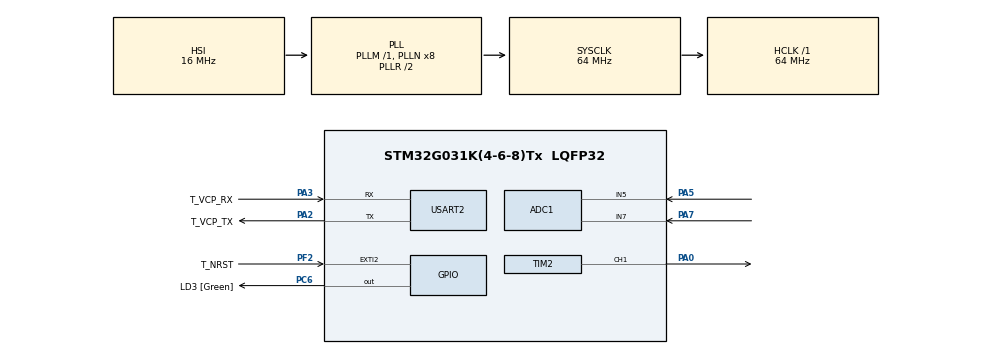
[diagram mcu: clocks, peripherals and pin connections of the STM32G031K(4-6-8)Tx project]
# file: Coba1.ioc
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ADC1.Channel-1\#ChannelRegularConversion=ADC_CHANNEL_7
ADC1.ContinuousConvMode=ENABLE
ADC1.NbrOfConversionFlag=1
ADC1.Rank-1\#ChannelRegularConversion=1
ADC1.SamplingTime-1\#ChannelRegularConversion=ADC_SAMPLINGTIME_COMMON_1
ADC1.SelectedChannel=ADC_CHANNEL_5|ADC_CHANNEL_7
ADC1.master=1
Mcu.Family=STM32G0
Mcu.Name=STM32G031K(4-6-8)Tx
Mcu.Package=LQFP32
NVIC.EXTI2_3_IRQn=true\:0\:0\:false\:false\:true\:true\:true
PA0.Signal=S_TIM2_CH1
PA13.GPIO_Label=T_JTMS
PA13.Mode=Serial_Wire
PA13.Signal=SYS_SWDIO
PA14-BOOT0.GPIO_Label=T_JTCK
PA14-BOOT0.Mode=Serial_Wire
PA14-BOOT0.Signal=SYS_SWCLK
PA2.GPIO_Label=T_VCP_TX
PA2.GPIO_PuPd=GPIO_PULLUP
PA2.Mode=Asynchronous
PA2.Signal=USART2_TX
PA3.GPIO_Label=T_VCP_RX
PA3.GPIO_PuPd=GPIO_PULLUP
PA3.Mode=Asynchronous
PA3.Signal=USART2_RX
PA5.Mode=IN5
PA5.Signal=ADC1_IN5
PA7.Mode=IN7
PA7.Signal=ADC1_IN7
PC14-OSC32_IN\ (PC14).Mode=LSE-External-Oscillator
PC14-OSC32_IN\ (PC14).Signal=RCC_OSC32_IN
PC15-OSC32_OUT\ (PC15).Mode=LSE-External-Oscillator
PC15-OSC32_OUT\ (PC15).Signal=RCC_OSC32_OUT
PC6.GPIO_Label=LD3 [Green]
PC6.Signal=GPIO_Output
PF2\ -\ NRST.GPIO_Label=T_NRST
PF2\ -\ NRST.GPIO_ModeDefaultEXTI=GPIO_MODE_IT_FALLING
PF2\ -\ NRST.GPIO_PuPd=GPIO_PULLUP
PF2\ -\ NRST.Signal=GPXTI2
ProjectManager.HeapSize=0x200
ProjectManager.StackSize=0x400
ProjectManager.TargetToolchain=MDK-ARM V5.27
RCC.ADCFreq_Value=64000000
RCC.AHBFreq_Value=64000000
RCC.APB1CLKDivider=RCC_HCLK_DIV2
RCC.CortexFreq_Value=64000000
RCC.EXTERNAL_CLOCK_VALUE=12288000
RCC.HCLKFreq_Value=64000000
RCC.HSE_VALUE=8000000
RCC.HSI_VALUE=16000000
RCC.SYSCLKFreq_VALUE=64000000
RCC.SYSCLKSource=RCC_SYSCLKSOURCE_PLLCLK
RCC.VCOOutputFreq_Value=128000000
SH.S_TIM2_CH1.0=TIM2_CH1,PWM Generation1 CH1
TIM1.Period=0xffff
TIM1.Prescaler=64-1
TIM2.AutoReloadPreload=TIM_AUTORELOAD_PRELOAD_ENABLE
TIM2.Channel-PWM\ Generation1\ CH1=TIM_CHANNEL_1
TIM2.Period=4294967295
USART2.VirtualMode-Asynchronous=VM_ASYNC
USART2.WordLength=WORDLENGTH_7B
VP_TIM1_VS_ClockSourceINT.Mode=Internal
board=NUCLEO-G031K8

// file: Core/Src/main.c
/* USER CODE BEGIN Header */
/**
  ******************************************************************************
  * @file           : main.c
  * @brief          : Main program body
  ******************************************************************************
  * @attention
  *
  * <h2><center>&copy; Copyright (c) 2022 STMicroelectronics.
  * All rights reserved.</center></h2>
  *
  * This software component is licensed by ST under BSD 3-Clause license,
  * the "License"; You may not use this file except in compliance with the
  * License. You may obtain a copy of the License at:
  *                        opensource.org/licenses/BSD-3-Clause
  *
  ******************************************************************************
  */
/* USER CODE END Header */
#include "main.h"

ADC_HandleTypeDef hadc1;

TIM_HandleTypeDef htim1;
TIM_HandleTypeDef htim2;

UART_HandleTypeDef huart2;

void SystemClock_Config(void);
static void MX_GPIO_Init(void);
static void MX_USART2_UART_Init(void);
static void MX_TIM1_Init(void);
static void MX_ADC1_Init(void);
static void MX_TIM2_Init(void);

/* USER CODE BEGIN 0 */
void delay_us (uint16_t us)
{
	__HAL_TIM_SET_COUNTER(&htim1,0);  // set the counter value a 0
	while (__HAL_TIM_GET_COUNTER(&htim1) < us);  // wait for the counter to reach the us input in the parameter
}

/*
void HAL_GPIO_EXTI_Falling_Callback(uint16_t GPIO_Pin)
{
    if(GPIO_Pin == GPIO_PIN_2) // If The INT Source Is EXTI Line9 (A9 Pin)
    {
			HAL_GPIO_TogglePin(GPIOC, GPIO_PIN_6); // Toggle The Output (LED) Pin
    }
}
*/
uint16_t AD_RES;
/* USER CODE END 0 */

int main(void)
{

  /* MCU Configuration--------------------------------------------------------*/

  /* Reset of all peripherals, Initializes the Flash interface and the Systick. */
  HAL_Init();

  /* Configure the system clock */
  SystemClock_Config();

  /* Initialize all configured peripherals */
  MX_GPIO_Init();
  MX_USART2_UART_Init();
  MX_TIM1_Init();
  MX_ADC1_Init();
  MX_TIM2_Init();
  /* USER CODE BEGIN 2 */
	HAL_TIM_Base_Start(&htim1);	// Start timer 1
	// Start ADC Conversion
	HAL_ADC_Start(&hadc1);
	//HAL_ADCEx_Calibration_Start(&hadc1);	// Calibrate ADC
  /* USER CODE END 2 */

  /* Infinite loop */
  /* USER CODE BEGIN WHILE */
  while (1)
  {
		// Poll ADC1 Perihperal & TimeOut = 1mSec
		HAL_ADC_PollForConversion(&hadc1, 1000);
		// Read The ADC Conversion Result & Map It To PWM DutyCycle
		AD_RES = HAL_ADC_GetValue(&hadc1);

		//HAL_GPIO_TogglePin(GPIOC, GPIO_PIN_6);
		//delay_us(65000);

    /* USER CODE END WHILE */

  }
}

void SystemClock_Config(void)
{
  RCC_OscInitTypeDef RCC_OscInitStruct = {0};
  RCC_ClkInitTypeDef RCC_ClkInitStruct = {0};
  RCC_PeriphCLKInitTypeDef PeriphClkInit = {0};

  /** Configure the main internal regulator output voltage
  */
  HAL_PWREx_ControlVoltageScaling(PWR_REGULATOR_VOLTAGE_SCALE1);
  /** Initializes the RCC Oscillators according to the specified parameters
  * in the RCC_OscInitTypeDef structure.
  */
  RCC_OscInitStruct.OscillatorType = RCC_OSCILLATORTYPE_HSI;
  RCC_OscInitStruct.HSIState = RCC_HSI_ON;
  RCC_OscInitStruct.HSIDiv = RCC_HSI_DIV1;
  RCC_OscInitStruct.HSICalibrationValue = RCC_HSICALIBRATION_DEFAULT;
  RCC_OscInitStruct.PLL.PLLState = RCC_PLL_ON;
  RCC_OscInitStruct.PLL.PLLSource = RCC_PLLSOURCE_HSI;
  RCC_OscInitStruct.PLL.PLLM = RCC_PLLM_DIV1;
  RCC_OscInitStruct.PLL.PLLN = 8;
  RCC_OscInitStruct.PLL.PLLP = RCC_PLLP_DIV2;
  RCC_OscInitStruct.PLL.PLLQ = RCC_PLLQ_DIV2;
  RCC_OscInitStruct.PLL.PLLR = RCC_PLLR_DIV2;
  if (HAL_RCC_OscConfig(&RCC_OscInitStruct) != HAL_OK)
  {
    Error_Handler();
  }
  /** Initializes the CPU, AHB and APB buses clocks
  */
  RCC_ClkInitStruct.ClockType = RCC_CLOCKTYPE_HCLK|RCC_CLOCKTYPE_SYSCLK
                              |RCC_CLOCKTYPE_PCLK1;
  RCC_ClkInitStruct.SYSCLKSource = RCC_SYSCLKSOURCE_PLLCLK;
  RCC_ClkInitStruct.AHBCLKDivider = RCC_SYSCLK_DIV1;
  RCC_ClkInitStruct.APB1CLKDivider = RCC_HCLK_DIV2;

  if (HAL_RCC_ClockConfig(&RCC_ClkInitStruct, FLASH_LATENCY_2) != HAL_OK)
  {
    Error_Handler();
  }
  /** Initializes the peripherals clocks
  */
  PeriphClkInit.PeriphClockSelection = RCC_PERIPHCLK_ADC|RCC_PERIPHCLK_TIM1;
  PeriphClkInit.AdcClockSelection = RCC_ADCCLKSOURCE_SYSCLK;
  PeriphClkInit.Tim1ClockSelection = RCC_TIM1CLKSOURCE_PCLK1;
  if (HAL_RCCEx_PeriphCLKConfig(&PeriphClkInit) != HAL_OK)
  {
    Error_Handler();
  }
}

static void MX_ADC1_Init(void)
{

  ADC_ChannelConfTypeDef sConfig = {0};

  /** Configure the global features of the ADC (Clock, Resolution, Data Alignment and number of conversion)
  */
  hadc1.Instance = ADC1;
  hadc1.Init.ClockPrescaler = ADC_CLOCK_SYNC_PCLK_DIV4;
  hadc1.Init.Resolution = ADC_RESOLUTION_12B;
  hadc1.Init.DataAlign = ADC_DATAALIGN_RIGHT;
  hadc1.Init.ScanConvMode = ADC_SCAN_DISABLE;
  hadc1.Init.EOCSelection = ADC_EOC_SINGLE_CONV;
  hadc1.Init.LowPowerAutoWait = DISABLE;
  hadc1.Init.LowPowerAutoPowerOff = DISABLE;
  hadc1.Init.ContinuousConvMode = ENABLE;
  hadc1.Init.NbrOfConversion = 1;
  hadc1.Init.DiscontinuousConvMode = DISABLE;
  hadc1.Init.ExternalTrigConv = ADC_SOFTWARE_START;
  hadc1.Init.ExternalTrigConvEdge = ADC_EXTERNALTRIGCONVEDGE_NONE;
  hadc1.Init.DMAContinuousRequests = DISABLE;
  hadc1.Init.Overrun = ADC_OVR_DATA_PRESERVED;
  hadc1.Init.SamplingTimeCommon1 = ADC_SAMPLETIME_1CYCLE_5;
  hadc1.Init.SamplingTimeCommon2 = ADC_SAMPLETIME_1CYCLE_5;
  hadc1.Init.OversamplingMode = DISABLE;
  hadc1.Init.TriggerFrequencyMode = ADC_TRIGGER_FREQ_HIGH;
  if (HAL_ADC_Init(&hadc1) != HAL_OK)
  {
    Error_Handler();
  }
  /** Configure Regular Channel
  */
  sConfig.Channel = ADC_CHANNEL_5;
  sConfig.Rank = ADC_REGULAR_RANK_1;
  sConfig.SamplingTime = ADC_SAMPLINGTIME_COMMON_1;
  if (HAL_ADC_ConfigChannel(&hadc1, &sConfig) != HAL_OK)
  {
    Error_Handler();
  }

}

static void MX_TIM1_Init(void)
{

  TIM_ClockConfigTypeDef sClockSourceConfig = {0};
  TIM_MasterConfigTypeDef sMasterConfig = {0};

  htim1.Instance = TIM1;
  htim1.Init.Prescaler = 64-1;
  htim1.Init.CounterMode = TIM_COUNTERMODE_UP;
  htim1.Init.Period = 0xffff;
  htim1.Init.ClockDivision = TIM_CLOCKDIVISION_DIV1;
  htim1.Init.RepetitionCounter = 0;
  htim1.Init.AutoReloadPreload = TIM_AUTORELOAD_PRELOAD_DISABLE;
  if (HAL_TIM_Base_Init(&htim1) != HAL_OK)
  {
    Error_Handler();
  }
  sClockSourceConfig.ClockSource = TIM_CLOCKSOURCE_INTERNAL;
  if (HAL_TIM_ConfigClockSource(&htim1, &sClockSourceConfig) != HAL_OK)
  {
    Error_Handler();
  }
  sMasterConfig.MasterOutputTrigger = TIM_TRGO_RESET;
  sMasterConfig.MasterOutputTrigger2 = TIM_TRGO2_RESET;
  sMasterConfig.MasterSlaveMode = TIM_MASTERSLAVEMODE_DISABLE;
  if (HAL_TIMEx_MasterConfigSynchronization(&htim1, &sMasterConfig) != HAL_OK)
  {
    Error_Handler();
  }

}

static void MX_TIM2_Init(void)
{

  TIM_MasterConfigTypeDef sMasterConfig = {0};
  TIM_OC_InitTypeDef sConfigOC = {0};

  htim2.Instance = TIM2;
  htim2.Init.Prescaler = 0;
  htim2.Init.CounterMode = TIM_COUNTERMODE_UP;
  htim2.Init.Period = 4294967295;
  htim2.Init.ClockDivision = TIM_CLOCKDIVISION_DIV1;
  htim2.Init.AutoReloadPreload = TIM_AUTORELOAD_PRELOAD_ENABLE;
  if (HAL_TIM_PWM_Init(&htim2) != HAL_OK)
  {
    Error_Handler();
  }
  sMasterConfig.MasterOutputTrigger = TIM_TRGO_RESET;
  sMasterConfig.MasterSlaveMode = TIM_MASTERSLAVEMODE_DISABLE;
  if (HAL_TIMEx_MasterConfigSynchronization(&htim2, &sMasterConfig) != HAL_OK)
  {
    Error_Handler();
  }
  sConfigOC.OCMode = TIM_OCMODE_PWM1;
  sConfigOC.Pulse = 0;
  sConfigOC.OCPolarity = TIM_OCPOLARITY_HIGH;
  sConfigOC.OCFastMode = TIM_OCFAST_DISABLE;
  if (HAL_TIM_PWM_ConfigChannel(&htim2, &sConfigOC, TIM_CHANNEL_1) != HAL_OK)
  {
    Error_Handler();
  }
  HAL_TIM_MspPostInit(&htim2);

}

static void MX_USART2_UART_Init(void)
{

  huart2.Instance = USART2;
  huart2.Init.BaudRate = 115200;
  huart2.Init.WordLength = UART_WORDLENGTH_7B;
  huart2.Init.StopBits = UART_STOPBITS_1;
  huart2.Init.Parity = UART_PARITY_NONE;
  huart2.Init.Mode = UART_MODE_TX_RX;
  huart2.Init.HwFlowCtl = UART_HWCONTROL_NONE;
  huart2.Init.OverSampling = UART_OVERSAMPLING_16;
  huart2.Init.OneBitSampling = UART_ONE_BIT_SAMPLE_DISABLE;
  huart2.Init.ClockPrescaler = UART_PRESCALER_DIV1;
  huart2.AdvancedInit.AdvFeatureInit = UART_ADVFEATURE_NO_INIT;
  if (HAL_UART_Init(&huart2) != HAL_OK)
  {
    Error_Handler();
  }

}

static void MX_GPIO_Init(void)
{
  GPIO_InitTypeDef GPIO_InitStruct = {0};

  /* GPIO Ports Clock Enable */
  __HAL_RCC_GPIOC_CLK_ENABLE();
  __HAL_RCC_GPIOF_CLK_ENABLE();
  __HAL_RCC_GPIOA_CLK_ENABLE();

  /*Configure GPIO pin Output Level */
  HAL_GPIO_WritePin(LD3_GPIO_Port, LD3_Pin, GPIO_PIN_RESET);

  /*Configure GPIO pin : T_NRST_Pin */
  GPIO_InitStruct.Pin = T_NRST_Pin;
  GPIO_InitStruct.Mode = GPIO_MODE_IT_FALLING;
  GPIO_InitStruct.Pull = GPIO_PULLUP;
  HAL_GPIO_Init(T_NRST_GPIO_Port, &GPIO_InitStruct);

  /*Configure GPIO pin : LD3_Pin */
  GPIO_InitStruct.Pin = LD3_Pin;
  GPIO_InitStruct.Mode = GPIO_MODE_OUTPUT_PP;
  GPIO_InitStruct.Pull = GPIO_NOPULL;
  GPIO_InitStruct.Speed = GPIO_SPEED_FREQ_LOW;
  HAL_GPIO_Init(LD3_GPIO_Port, &GPIO_InitStruct);

  /* EXTI interrupt init*/
  HAL_NVIC_SetPriority(EXTI2_3_IRQn, 0, 0);
  HAL_NVIC_EnableIRQ(EXTI2_3_IRQn);

}

void Error_Handler(void)
{
  __disable_irq();
  while (1)
  {
  }
}

/************************ (C) COPYRIGHT STMicroelectronics *****END OF FILE****/
